# AU302NDF51 register map
File version: 1.0
Registers are 32-bit, access per field, reset 0x0 unless marked. A register's access mark holds for its fields unless they carry their own. Offsets are from the block's base; [hi:lo] are bit positions; {n}, {i} and the like mark numbered series.

## PGA0 — PGA_CFG peripheral interface
Base 0x18200000
Same registers: PGA1 0x18201000, PGA2 0x18202000
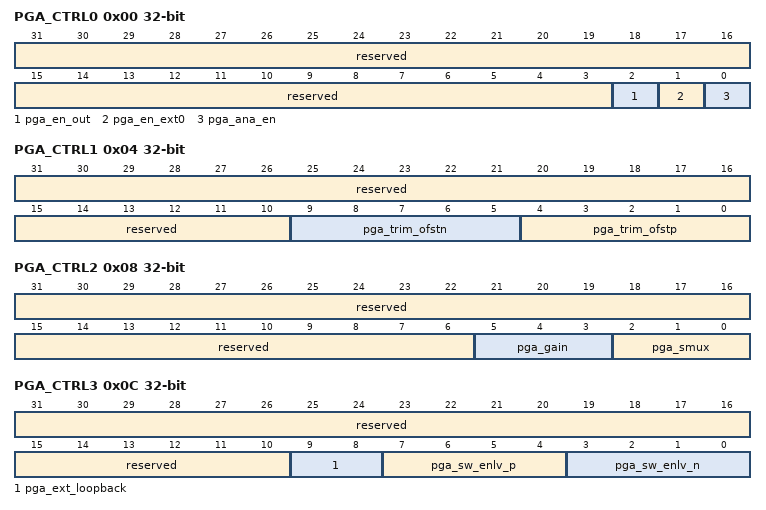
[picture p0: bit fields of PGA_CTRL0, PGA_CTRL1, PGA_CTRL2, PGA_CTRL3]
0x00 PGA_CTRL0 — PGA控制寄存器0。
  [31:3] reserved ro — 保留。
  [2] pga_en_out rw — PGA输出使能。 0：不使能； 1：使能；
  [1] pga_en_ext0 rw — PGA外部输出使能。 0：不使能； 1：使能；
  [0] pga_ana_en rw — PGA总体的使能。 0：不使能； 1：使能；
0x04 PGA_CTRL1 — PGA控制寄存器1。
  [31:10] reserved ro — 保留。
  [9:5] pga_trim_ofstn rw — PGA trim NMOS offset。
  [4:0] pga_trim_ofstp rw — PGA trim PMOS offset。
0x08 PGA_CTRL2 — PGA控制寄存器2。
  [31:6] reserved ro — 保留。
  [5:3] pga_gain rw — PGA增益。 000：1； 001：2； 010：4； 011：8； 100~111：16。
  [2:0] pga_smux rw — PGA输入通道选择。 000：选择内部电阻，选择VIP0/VIN0 通道； 001：选择内部电阻，选择VIP1/VIN1 通道； 010：选择内部电阻，选择VIP2/VIN2 通道； 011：选择内部电阻，选择VIP3/VIN3 通道； 100：选择外部电阻，选择VIP1/VIN0 通道； 101：选择外部电阻，选择VIP1/VIN1 通道； 110：选择外部电阻，选择VIP2/VIN2 通道； 111：选择外部电阻，选择VIP3/VIN3 通道。
0x0C PGA_CTRL3 — PGA SW控制寄存器。
  [31:10] reserved ro — 保留。
  [9:8] pga_ext_loopback rw — PGA环回开关，bit[8]控制通道0，bit[9]控制通道3，仅在外置电阻时需要使能。 00：通道0和3均不使能； 01：通道0使能，通道3不使能； 10：通道0不使能，通道3使能； 11：通道0和3均使能。
  [7:4] pga_sw_enlv_p rw — PGA P输入SW开关使能，与通道选择联合配置。 0x1：VINP[0]； 0x2：VINP[1]； 0x4：VINP[2]； 0x8：VINP[3]； 其他：保留。
  [3:0] pga_sw_enlv_n rw — PGA N输入SW开关使能，与通道选择联合配置。 0x1：VINN[0]； 0x2：VINN[1]； 0x4：VINN[2]； 0x8：VINN[3]； 其他：保留。

## PMC — PMC_REG peripheral interface
Base 0x147E0000
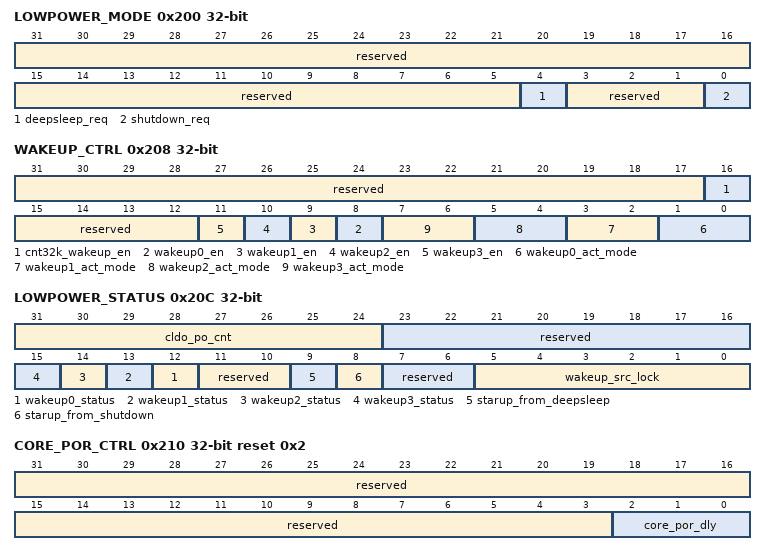
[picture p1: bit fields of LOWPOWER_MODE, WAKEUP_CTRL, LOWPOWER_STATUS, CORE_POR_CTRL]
0x200 LOWPOWER_MODE — 低功耗模式控制寄存器。
  [31:5] reserved ro — 保留。
  [4] deepsleep_req wo — 系统进入deepsleep模式请求。 对此寄存器位域写1操作将触发芯片进入deepsleep模式流程。
  [3:1] reserved ro — 保留。
  [0] shutdown_req wo — 系统进入shutdown模式请求。 对此寄存器位域写1操作将触发芯片进入shutdown模式流程。
0x204 CNT32K_WAKE_CYC rw reset 0xFFFF — 定时唤醒周期设置寄存器。
  [31:0] cnt32k_wakeup_cycle — 定时唤醒周期数（计数时钟clk_losc）。
0x208 WAKEUP_CTRL — deepsleep模式唤醒控制寄存器。
  [31:17] reserved ro — 保留。
  [16] cnt32k_wakeup_en rw — 定时唤醒使能。 0：不使能； 1：使能。
  [15:12] reserved ro — 保留。
  [n+8] wakeup{n}_en rw (n=0..3) — WAKEUP{n}使能。 0：不使能； 1：使能。
  [2n+1:2n] wakeup{n}_act_mode rw (n=0..3) — WAKEUP{n}有效模式选择。 00：上升沿有效； 01：下降沿有效； 10：高电平有效； 11：低电平有效。
0x20C LOWPOWER_STATUS ro — 低功耗状态查询寄存器。
  [31:24] cldo_po_cnt — cldo上电时间统计。
  [23:16] reserved — 保留。
  [n+12] wakeup{n}_status (n=0..3) — wakeup{n}唤醒源状态。 1：唤醒源高电平； 0：唤醒源低电平。
  [11:10] reserved — 保留。
  [9] starup_from_deepsleep — 从deepsleep状态启动标识。 1：从deepsleep模式启动； 0：未从deepsleep模式启动。
  [8] starup_from_shutdown — 从shutdown状态启动标识。 1：从shutdown模式启动； 0：未从shutdown模式启动。
  [7:6] reserved — 保留。
  [5:0] wakeup_src_lock — 启动唤醒源查询。 bit[5]：RESETN管脚唤醒； bit[4]：WAKEUP3唤醒； bit[3]：WAKEUP2唤醒； bit[2]：WAKEUP1唤醒； bit[1]：WAKEUP0唤醒； bit[0]：cnt32k定时唤醒。
0x210 CORE_POR_CTRL reset 0x2 — CORE域POR复位时长设置寄存器。
  [31:3] reserved ro — 保留。
  [2:0] core_por_dly rw — CORE域上电复位时长设置，以ms为单位。配置为0无效。
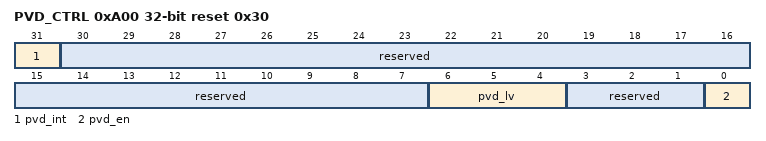
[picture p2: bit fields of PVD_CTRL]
0xA00 PVD_CTRL reset 0x30 — PVD控制寄存器。
  [31] pvd_int ro — PVD中断状态。
  [30:7] reserved ro — 保留。
  [6:4] pvd_lv rw — PVD 电压阈值。 000： rising edge 2.18V, falling edge 2.08V (NO USE)； 001： rising edge 2.28V, falling edge 2.18V (NO USE)； 010： rising edge 2.38V, falling edge 2.28V； 011： rising edge 2.48V, falling edge 2.38V； 100： rising edge 2.58V, falling edge 2.48V； 101： rising edge 2.68V, falling edge 2.58V； 110： rising edge 2.78V, falling edge 2.68V； 111： rising edge 2.88V, falling edge 2.78V。
  [3:1] reserved ro — 保留。
  [0] pvd_en rw — PVD使能。 0：不使能； 1：使能。
{0xF00+4i} AON_USER_REG{i} rw (i=0..3) — AON域用户寄存器{i}。
  [31:0] aon_user_reg{i} — AON电源域通用寄存器{i}。

## SYSCTRL0 — SYSCTRL0_REG peripheral interface
Base 0x10100000
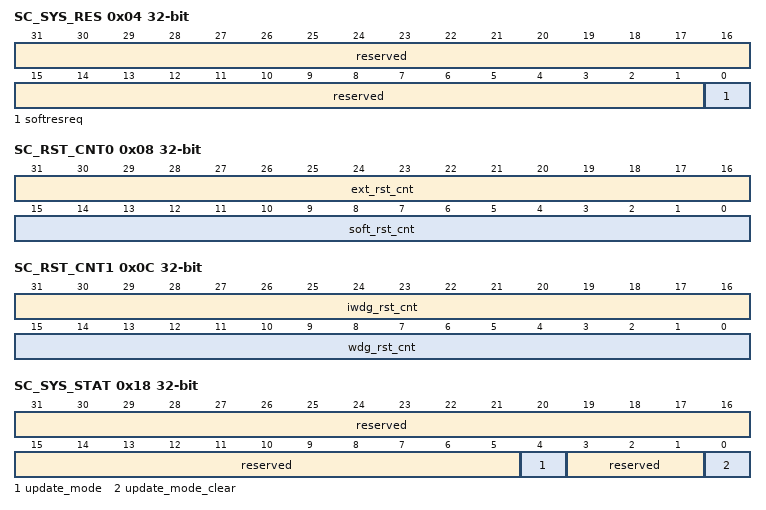
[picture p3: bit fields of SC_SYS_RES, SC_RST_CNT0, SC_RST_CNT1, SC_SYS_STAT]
0x04 SC_SYS_RES — 系统软复位寄存器。 Note：该寄存器可被寄存器SC_LOCKEN.sc_cfg_lock写保护，只有禁用写保护时，对这个寄存器的写操作才有效。
  [31:1] reserved ro — 保留。
  [0] softresreq rw — 对此寄存器位域的任意写操作都会导致系统软复位。
0x08 SC_RST_CNT0 ro — 复位次数统计寄存器0。
  [31:16] ext_rst_cnt — RESETN管脚复位次数统计。
  [15:0] soft_rst_cnt — 软复位次数统计。
0x0C SC_RST_CNT1 ro — 复位次数统计寄存器1。
  [31:16] iwdg_rst_cnt — iwdg复位次数统计。
  [15:0] wdg_rst_cnt — wdg复位次数统计。
0x18 SC_SYS_STAT — 系统启动模式寄存器。
  [31:5] reserved ro — 保留。
  [4] update_mode ro — 系统升级标识，芯片上电时锁存。 0：不升级，直接启动模式； 1：升级模式。 注：当处于升级模式时，芯片JTAG相关管脚强制为JTAG功能，无法软件切换为其他复用功能。
  [3:1] reserved ro — 保留。
  [0] update_mode_clear rw — 系统升级标识清除寄存器，芯片上电完成后生效。 0：不清除； 1：清除。
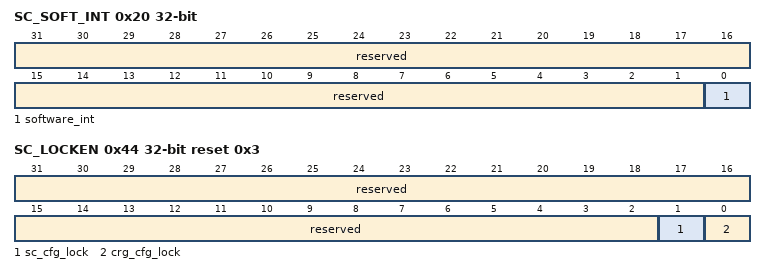
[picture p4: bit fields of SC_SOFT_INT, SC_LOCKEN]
0x20 SC_SOFT_INT — 软中断寄存器。
  [31:1] reserved ro — 保留。
  [0] software_int rw — 软件中断寄存器。 向此寄存器位域写入1产生软件中断。
0x24 SC_SOFT_EVT_ID rw — 软中断事件ID寄存器。
  [31:0] swint_evt_id — 软中断事件ID，可用于软中断事件类型定义。
0x44 SC_LOCKEN reset 0x3 — 关键寄存器的锁定寄存器。 Note：仅当使写操作数为0xEA51_xxxx（xxxx为目标期望值），才能对[15:0]位域进行写操作。
  [31:2] reserved ro — 保留。
  [1] sc_cfg_lock rw — SYSCTRL相关寄存器写保护。 0：写使能； 1：写禁止。
  [0] crg_cfg_lock rw — CRG相关寄存器写保护。 0：写使能； 1：写禁止。
0x200 SC_HRST_REG0 rw — SC专用硬复位寄存器0。 （CH）该寄存器不会被系统软件复位所复位。
  [31:0] sc_hrst_reg0 — 系统正常启动时，如果检测到此寄存器值为0xA5A5A5A5，则CPU将停止启动系统，此时可以通过JTAG/SWD接口调试（或烧写）系统。
0xE00 USER_POR_REG0 rw — USER专用POR复位寄存器0。 （CH）该寄存器仅被POR复位或从低功耗模式唤醒时复位。
  [31:0] user_por_reg0 — USER专用REG0。
0xE04 USER_POR_REG1 rw — USER专用POR复位寄存器1。 （CH）该寄存器仅被POR复位或从低功耗模式唤醒时复位。
  [31:0] user_por_reg1 — USER专用REG1。
0xE40 USER_HRST_REG0 rw — USER专用硬复位寄存器0。 （CH）该寄存器不会被系统软复位所复位。
  [31:0] user_hrst_reg0 — USER专用REG2。
0xE44 USER_HRST_REG1 rw — USER专用硬复位寄存器1。 （CH）该寄存器不会被系统软复位所复位。
  [31:0] user_hrst_reg1 — USER专用REG3。
0xE80 USER_REG0 rw — USER专用寄存器0。
  [31:0] user_reg0 — USER专用REG4。
0xE84 USER_REG1 rw — USER专用寄存器1。
  [31:0] user_reg1 — USER专用REG5。
